# nrf5340 register map
Vendor: Nordic Semiconductor; Series: nrf53; File version: 1
CPU: CM33 r0p2, little endian, MPU, FPU, 3 interrupt priority bits
Registers are 32-bit, read-write, reset 0x0 unless marked. A register's access mark holds for its fields unless they carry their own. Offsets are from the block's base; [hi:lo] are bit positions; {n}, {i} and the like mark numbered series; 'fields as' and 'values as' point back to an identical list; <NAME> marks a mode.

## COMP_NS — Comparator 0
Base 0x4001A000
Same registers: COMP_S 0x5001A000
0x00 TASKS_START wo — Start comparator
  [0] TASKS_START
    1=Trigger task
0x04 TASKS_STOP wo — Stop comparator
  [0] TASKS_STOP
    1=Trigger task
0x08 TASKS_SAMPLE wo — Sample comparator value
  [0] TASKS_SAMPLE
    1=Trigger task
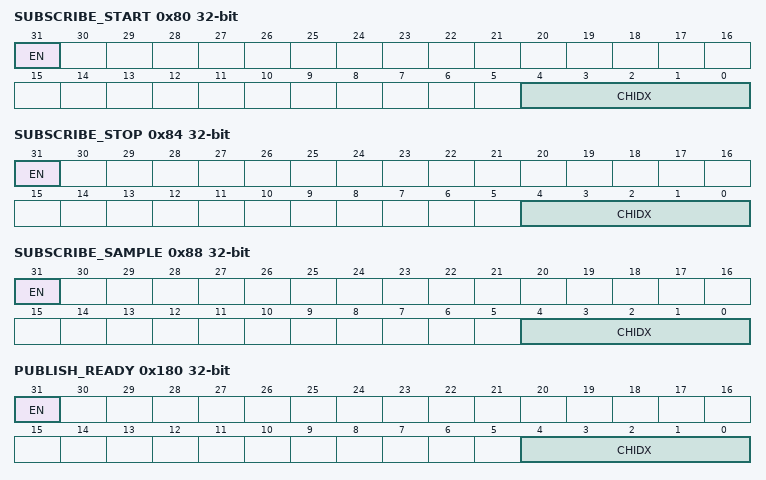
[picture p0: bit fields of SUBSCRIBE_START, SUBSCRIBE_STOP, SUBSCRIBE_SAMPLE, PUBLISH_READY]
0x80 SUBSCRIBE_START — Subscribe configuration for task START
  [31] EN
    0=Disabled (Disable subscription); 1=Enabled (Enable subscription)
  [4:0] CHIDX — Channel that task START will subscribe to
0x84 SUBSCRIBE_STOP — Subscribe configuration for task STOP
  [31] EN
    values as SUBSCRIBE_START.EN
  [4:0] CHIDX — Channel that task STOP will subscribe to
0x88 SUBSCRIBE_SAMPLE — Subscribe configuration for task SAMPLE
  [31] EN
    values as SUBSCRIBE_START.EN
  [4:0] CHIDX — Channel that task SAMPLE will subscribe to
0x100 EVENTS_READY — COMP is ready and output is valid
  [0] EVENTS_READY
    0=NotGenerated (Event not generated); 1=Generated (Event generated)
0x104 EVENTS_DOWN — Downward crossing
  [0] EVENTS_DOWN
    values as EVENTS_READY.EVENTS_READY
0x108 EVENTS_UP — Upward crossing
  [0] EVENTS_UP
    values as EVENTS_READY.EVENTS_READY
0x10C EVENTS_CROSS — Downward or upward crossing
  [0] EVENTS_CROSS
    values as EVENTS_READY.EVENTS_READY
0x180 PUBLISH_READY — Publish configuration for event READY
  [31] EN
    0=Disabled (Disable publishing); 1=Enabled (Enable publishing)
  [4:0] CHIDX — Channel that event READY will publish to.
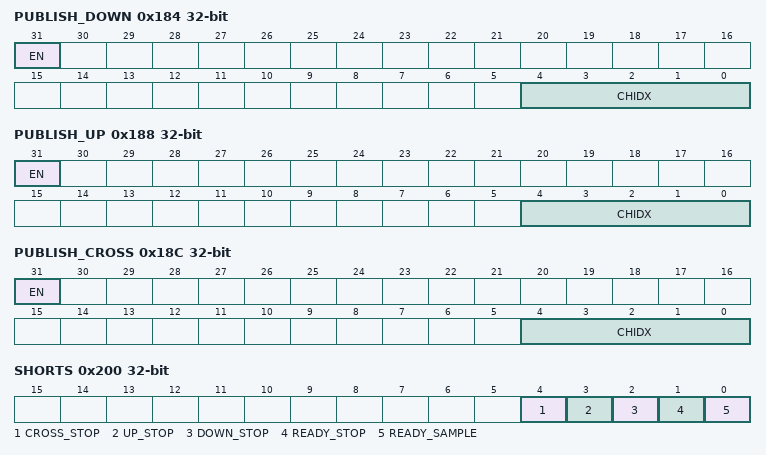
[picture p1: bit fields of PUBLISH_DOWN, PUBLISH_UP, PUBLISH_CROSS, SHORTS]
0x184 PUBLISH_DOWN — Publish configuration for event DOWN
  [31] EN
    values as PUBLISH_READY.EN
  [4:0] CHIDX — Channel that event DOWN will publish to.
0x188 PUBLISH_UP — Publish configuration for event UP
  [31] EN
    values as PUBLISH_READY.EN
  [4:0] CHIDX — Channel that event UP will publish to.
0x18C PUBLISH_CROSS — Publish configuration for event CROSS
  [31] EN
    values as PUBLISH_READY.EN
  [4:0] CHIDX — Channel that event CROSS will publish to.
0x200 SHORTS — Shortcuts between local events and tasks
  [all] fields
    0=Disabled (Disable shortcut); 1=Enabled (Enable shortcut)
  [4] CROSS_STOP — Shortcut between event CROSS and task STOP
  [3] UP_STOP — Shortcut between event UP and task STOP
  [2] DOWN_STOP — Shortcut between event DOWN and task STOP
  [1] READY_STOP — Shortcut between event READY and task STOP
  [0] READY_SAMPLE — Shortcut between event READY and task SAMPLE
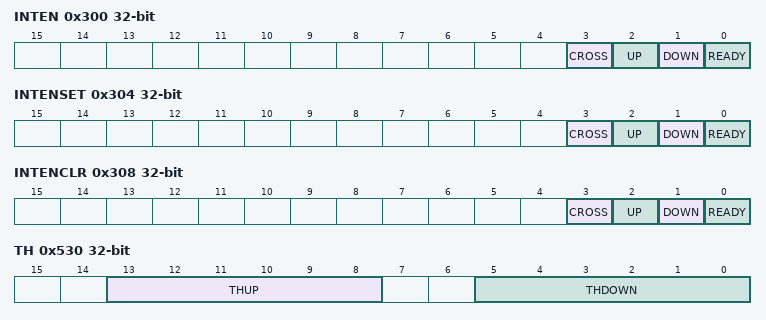
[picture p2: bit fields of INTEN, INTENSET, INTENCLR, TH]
0x300 INTEN — Enable or disable interrupt
  [all] fields
    0=Disabled; 1=Enabled
  [3] CROSS — Enable or disable interrupt for event CROSS
  [2] UP — Enable or disable interrupt for event UP
  [1] DOWN — Enable or disable interrupt for event DOWN
  [0] READY — Enable or disable interrupt for event READY
0x304 INTENSET — Enable interrupt
  [all] fields
    on read: 0=Disabled (Read: Disabled); 1=Enabled (Read: Enabled) | on write: 1=Set (Enable)
  [3] CROSS — Write '1' to enable interrupt for event CROSS
  [2] UP — Write '1' to enable interrupt for event UP
  [1] DOWN — Write '1' to enable interrupt for event DOWN
  [0] READY — Write '1' to enable interrupt for event READY
0x308 INTENCLR — Disable interrupt
  [all] fields
    on read: 0=Disabled (Read: Disabled); 1=Enabled (Read: Enabled) | on write: 1=Clear (Disable)
  [3] CROSS — Write '1' to disable interrupt for event CROSS
  [2] UP — Write '1' to disable interrupt for event UP
  [1] DOWN — Write '1' to disable interrupt for event DOWN
  [0] READY — Write '1' to disable interrupt for event READY
0x400 RESULT ro — Compare result
  [0] RESULT — Result of last compare. Decision point SAMPLE task.
    0=Below (Input voltage is below the threshold (VIN+ < VIN-)); 1=Above (Input voltage is above the threshold (VIN+ > VIN-))
0x404 BGREADY ro — COMP module is ready
  [0] STATE — Result of last compare. Decision point SAMPLE task.
    0=NotReady (Module is not ready); 1=Ready (Module is ready)
0x500 ENABLE — COMP enable
  [1:0] ENABLE — Enable or disable COMP
    0=Disabled; 2=Enabled
0x504 PSEL — Pin select
  [2:0] PSEL — Analog pin select
    {v}=AnalogInput{v} (AIN{v} selected as analog input) (v=0..6); 7=VddDiv2 (VDD/2 selected as analog input)
0x508 REFSEL reset 0x4 — Reference source select for single-ended mode
  [2:0] REFSEL — Reference select
    0=Int1V2 (VREF = internal 1.2 V reference (VDD >= 1.7 V)); 1=Int1V8 (VREF = internal 1.8 V reference (VDD >= VREF + 0.2 V)); 2=Int2V4 (VREF = internal 2.4 V reference (VDD >= VREF + 0.2 V)); 4=VDD (VREF = VDD); 5=ARef (VREF = AREF (VDD >= VREF >= AREFMIN))
0x50C EXTREFSEL — External reference select
  [2:0] EXTREFSEL — External analog reference select
    {v}=AnalogReference{v} (Use AIN{v} as external analog reference) (v=0..7)
0x530 TH — Threshold configuration for hysteresis unit
  [13:8] THUP — VUP = (THUP+1)/64*VREF
  [5:0] THDOWN — VDOWN = (THDOWN+1)/64*VREF
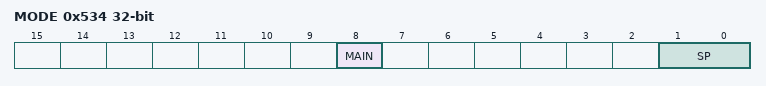
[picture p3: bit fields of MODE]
0x534 MODE — Mode configuration
  [8] MAIN — Main operation modes
    0=SE (Single-ended mode); 1=Differential mode
  [1:0] SP — Speed and power modes
    0=Low (Low-power mode); 1=Normal mode; 2=High-speed mode
0x538 HYST — Comparator hysteresis enable
  [0] HYST — Comparator hysteresis
    0=NoHyst (Comparator hysteresis disabled); 1=Hyst50mV (Comparator hysteresis enabled)
0x53C ISOURCE — Current source select on analog input
  [1:0] ISOURCE — Comparator hysteresis
    0=Off (Current source disabled); 1=Ien2mA5 (Current source enabled (+/- 2.5 uA)); 2=Ien5mA (Current source enabled (+/- 5 uA)); 3=Ien10mA (Current source enabled (+/- 10 uA))
0x540 REFTRIM reset 0x10 — Trim internal band gap reference, copied from FICR (COMPREFTRIM register) at reset
  [4:0] REFTRIM — Trimming value
0x544 ATECOMP — Analog test bus control for comparator
  [1:0] COMP — Configure connection of comparator to analog test bus
    0=Disconnected; 1=VIN (Connect VIN+ to ATB0 and VIN- to ATB1 (VIN- only in differential mode)); 2=VRef (Connect internal bandgap voltage to ATB0); 3=Future (Reserved for future use)
0xFFC POWER reset 0x1 — Peripheral power control
  [0] POWER — Peripheral power control. The peripheral and its registers will be reset to its initial state by switching the peripheral off and then back on again.
    0=Disabled (Peripheral is powered off); 1=Enabled (Peripheral is powered on)

## LPCOMP_NS — Low Power Comparator 0
Base 0x4001A000; alternate view of COMP_NS
Same registers: LPCOMP_S 0x5001A000 (alternate view of COMP_S)
Registers as COMP_NS, without BGREADY, TH, MODE, ISOURCE, REFTRIM, ATECOMP; these are added or differ:
0x100 EVENTS_READY — LPCOMP is ready and output is valid
  [0] EVENTS_READY
    0=NotGenerated (Event not generated); 1=Generated (Event generated)
0x400 RESULT ro — Compare result
  [0] RESULT — Result of last compare. Decision point SAMPLE task.
    0=Below (Input voltage is below the reference threshold (VIN+ < VIN-).); 1=Above (Input voltage is above the reference threshold (VIN+ > VIN-).)
0x500 ENABLE — Enable LPCOMP
  [1:0] ENABLE — Enable or disable LPCOMP
    0=Disabled; 1=Enabled
0x504 PSEL — Input pin select
  [2:0] PSEL — Analog pin select
    {v}=AnalogInput{v} (AIN{v} selected as analog input) (v=0..7)
0x508 REFSEL reset 0x4 — Reference select
  [3:0] REFSEL
    {v}=Ref{v+1}_8Vdd (VDD * {v+1}/8 selected as reference) (v=0..6); 7=ARef (External analog reference selected); 8=Ref1_16Vdd (VDD * 1/16 selected as reference); 9=Ref3_16Vdd (VDD * 3/16 selected as reference); 10=Ref5_16Vdd (VDD * 5/16 selected as reference); 11=Ref7_16Vdd (VDD * 7/16 selected as reference); 12=Ref9_16Vdd (VDD * 9/16 selected as reference); 13=Ref11_16Vdd (VDD * 11/16 selected as reference); 14=Ref13_16Vdd (VDD * 13/16 selected as reference); 15=Ref15_16Vdd (VDD * 15/16 selected as reference)
0x520 ANADETECT — Analog detect configuration
  [1:0] ANADETECT
    0=Cross (Generate ANADETECT on crossing, both upward crossing and downward crossing); 1=Up (Generate ANADETECT on upward crossing only); 2=Down (Generate ANADETECT on downward crossing only)
0x538 HYST — Comparator hysteresis enable
  [0] HYST
    0=Disabled (Comparator hysteresis disabled); 1=Enabled (Comparator hysteresis enabled)
